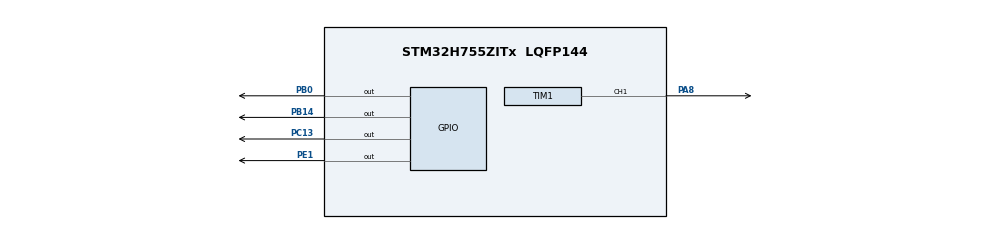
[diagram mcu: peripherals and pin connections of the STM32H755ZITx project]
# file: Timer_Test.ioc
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CortexM4.IPs=FATFS_M4\:I,FREERTOS_M4\:I,IWDG2\:I,RCC,WWDG2\:I,DMA,BDMA,MDMA,NVIC2\:I,USART3,DEBUG,PDM2PCM_M4\:I,PWR,RESMGR_UTILITY,SYS_M4\:I,USB_DEVICE_M4\:I,USB_HOST_M4\:I,CORTEX_M4\:I,GPIO,OPENAMP_M4\:I,VREFBUF,NUCLEO-H755ZI-Q
CortexM4.Pins=PB14
CortexM7.IPs=FATFS_M7\:I,FREERTOS_M7\:I,IWDG1\:I,RCC\:I,WWDG1\:I,DMA\:I,BDMA\:I,MDMA\:I,NVIC1\:I,USART3\:I,SYS\:I,CORTEX_M7\:I,DEBUG\:I,PDM2PCM_M7\:I,PWR\:I,RESMGR_UTILITY\:I,USB_DEVICE_M7\:I,USB_HOST_M7\:I,GPIO\:I,OPENAMP_M7\:I,VREFBUF\:I,NUCLEO-H755ZI-Q\:I,MEMORYMAP\:I,TIM1\:I
CortexM7.Pins=PC13,PB0,PE1
Mcu.Family=STM32H7
Mcu.Name=STM32H755ZITx
Mcu.Package=LQFP144
NUCLEO-H755ZI-Q.BUTTON=0
NUCLEO-H755ZI-Q.LD1=false
NUCLEO-H755ZI-Q.LD2=false
NUCLEO-H755ZI-Q.LD3=false
NUCLEO-H755ZI-Q.VCP=true
NVIC1.PriorityGroup=NVIC_PRIORITYGROUP_4
NVIC2.PriorityGroup=NVIC_PRIORITYGROUP_4
PA13\ (JTMS/SWDIO).Mode=Serial_Wire
PA13\ (JTMS/SWDIO).PinAttribute=CortexM7
PA13\ (JTMS/SWDIO).Signal=DEBUG_JTMS-SWDIO
PA14\ (JTCK/SWCLK).Mode=Serial_Wire
PA14\ (JTCK/SWCLK).PinAttribute=CortexM7
PA14\ (JTCK/SWCLK).Signal=DEBUG_JTCK-SWCLK
PA8.PinAttribute=CortexM7
PA8.Signal=S_TIM1_CH1
PB0.PinAttribute=CortexM7
PB0.Signal=GPIO_Output
PB13.Signal=ETH_TXD1
PB14.PinAttribute=CortexM4
PB14.Signal=GPIO_Output
PC13.PinAttribute=CortexM7
PC13.Signal=GPIO_Output
PC14-OSC32_IN\ (OSC32_IN).PinAttribute=Free
PC14-OSC32_IN\ (OSC32_IN).Signal=RCC_OSC32_IN
PC15-OSC32_OUT\ (OSC32_OUT).PinAttribute=Free
PC15-OSC32_OUT\ (OSC32_OUT).Signal=RCC_OSC32_OUT
PD8.Signal=USART3_TX
PD9.Signal=USART3_RX
PE1.PinAttribute=CortexM7
PE1.Signal=GPIO_Output
PH0-OSC_IN\ (PH0).PinAttribute=Free
PH0-OSC_IN\ (PH0).Signal=RCC_OSC_IN
PH1-OSC_OUT\ (PH1).PinAttribute=Free
PH1-OSC_OUT\ (PH1).Signal=RCC_OSC_OUT
ProjectManager.HeapSize=M4-0x200,M7-0x200
ProjectManager.StackSize=M4-0x400,M7-0x400
ProjectManager.TargetToolchain=STM32CubeIDE
RCC.ADCFreq_Value=129000000
RCC.APB1Freq_Value=100000000
RCC.APB2Freq_Value=100000000
RCC.APB3Freq_Value=100000000
RCC.APB4Freq_Value=100000000
RCC.CortexFreq_Value=400000000
RCC.D1PPRE=RCC_APB3_DIV2
RCC.D2PPRE1=RCC_APB1_DIV2
RCC.D2PPRE2=RCC_APB2_DIV2
RCC.D3PPRE=RCC_APB4_DIV2
RCC.DIVM1=4
RCC.DIVN1=50
RCC.DIVQ1=5
RCC.HCLKFreq_Value=200000000
RCC.HPRE=RCC_HCLK_DIV2
RCC.PLL2FRACN=0
RCC.PLL3FRACN=0
RCC.PLLFRACN=0
RCC.SYSCLKFreq_VALUE=400000000
RCC.SYSCLKSource=RCC_SYSCLKSOURCE_PLLCLK
RCC.SupplySource=PWR_DIRECT_SMPS_SUPPLY
RCC.USBFreq_Value=160000000
SH.S_TIM1_CH1.0=TIM1_CH1,PWM Generation1 CH1
TIM1.Channel-PWM\ Generation1\ CH1=TIM_CHANNEL_1
TIM1.ClockDivision=TIM_CLOCKDIVISION_DIV1
TIM1.Period=19
TIM1.Prescaler=4
TIM1.Pulse-PWM\ Generation1\ CH1=10
VP_MEMORYMAP_VS_MEMORYMAP.Mode=CurAppReg
VP_NUCLEO-H755ZI-Q_VS_BSP_COMMON.Mode=COMMON
VP_SYS_M4_VS_Systick.Mode=SysTick
VP_TIM1_VS_ClockSourceINT.Mode=Internal
board=NUCLEO-H755ZI-Q

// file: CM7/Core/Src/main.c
/* USER CODE BEGIN Header */
/**
  ******************************************************************************
  * @file           : main.c
  * @brief          : Main program body
  ******************************************************************************
  * @attention
  *
  * Copyright (c) 2025 STMicroelectronics.
  * All rights reserved.
  *
  * This software is licensed under terms that can be found in the LICENSE file
  * in the root directory of this software component.
  * If no LICENSE file comes with this software, it is provided AS-IS.
  *
  ******************************************************************************
  */
/* USER CODE END Header */
#include "main.h"

/* USER CODE BEGIN PD */

#ifndef HSEM_ID_0
#define HSEM_ID_0 (0U) /* HW semaphore 0*/
#endif

/* USER CODE END PD */

COM_InitTypeDef BspCOMInit;

TIM_HandleTypeDef htim1;

void SystemClock_Config(void);
static void MX_GPIO_Init(void);
static void MX_TIM1_Init(void);

int main(void)
{

/* USER CODE BEGIN Boot_Mode_Sequence_0 */
  int32_t timeout;
/* USER CODE END Boot_Mode_Sequence_0 */

/* USER CODE BEGIN Boot_Mode_Sequence_1 */
  /* Wait until CPU2 boots and enters in stop mode or timeout*/
  timeout = 0xFFFF;
  while((__HAL_RCC_GET_FLAG(RCC_FLAG_D2CKRDY) != RESET) && (timeout-- > 0));
  if ( timeout < 0 )
  {
  Error_Handler();
  }
/* USER CODE END Boot_Mode_Sequence_1 */
  /* MCU Configuration--------------------------------------------------------*/

  /* Reset of all peripherals, Initializes the Flash interface and the Systick. */
  HAL_Init();

  /* Configure the system clock */
  SystemClock_Config();
/* USER CODE BEGIN Boot_Mode_Sequence_2 */
/* When system initialization is finished, Cortex-M7 will release Cortex-M4 by means of
HSEM notification */
/*HW semaphore Clock enable*/
__HAL_RCC_HSEM_CLK_ENABLE();
/*Take HSEM */
HAL_HSEM_FastTake(HSEM_ID_0);
/*Release HSEM in order to notify the CPU2(CM4)*/
HAL_HSEM_Release(HSEM_ID_0,0);
/* wait until CPU2 wakes up from stop mode */
timeout = 0xFFFF;
while((__HAL_RCC_GET_FLAG(RCC_FLAG_D2CKRDY) == RESET) && (timeout-- > 0));
if ( timeout < 0 )
{
Error_Handler();
}
/* USER CODE END Boot_Mode_Sequence_2 */

  /* Initialize all configured peripherals */
  MX_GPIO_Init();
  MX_TIM1_Init();

  /* Initialize COM1 port (115200, 8 bits (7-bit data + 1 stop bit), no parity */
  BspCOMInit.BaudRate   = 115200;
  BspCOMInit.WordLength = COM_WORDLENGTH_8B;
  BspCOMInit.StopBits   = COM_STOPBITS_1;
  BspCOMInit.Parity     = COM_PARITY_NONE;
  BspCOMInit.HwFlowCtl  = COM_HWCONTROL_NONE;
  if (BSP_COM_Init(COM1, &BspCOMInit) != BSP_ERROR_NONE)
  {
    Error_Handler();
  }

  /* Infinite loop */
  while (1)
  {

    /* USER CODE BEGIN 3 */
	  HAL_GPIO_TogglePin(GPIOB, GPIO_PIN_0);
	  HAL_Delay(1000);
	  printf("Hello_Word");
  }
  /* USER CODE END 3 */
}

void SystemClock_Config(void)
{
  RCC_OscInitTypeDef RCC_OscInitStruct = {0};
  RCC_ClkInitTypeDef RCC_ClkInitStruct = {0};

  /** Supply configuration update enable
  */
  HAL_PWREx_ConfigSupply(PWR_DIRECT_SMPS_SUPPLY);

  /** Configure the main internal regulator output voltage
  */
  __HAL_PWR_VOLTAGESCALING_CONFIG(PWR_REGULATOR_VOLTAGE_SCALE1);

  while(!__HAL_PWR_GET_FLAG(PWR_FLAG_VOSRDY)) {}

  /** Initializes the RCC Oscillators according to the specified parameters
  * in the RCC_OscInitTypeDef structure.
  */
  RCC_OscInitStruct.OscillatorType = RCC_OSCILLATORTYPE_HSI;
  RCC_OscInitStruct.HSIState = RCC_HSI_DIV1;
  RCC_OscInitStruct.HSICalibrationValue = RCC_HSICALIBRATION_DEFAULT;
  RCC_OscInitStruct.PLL.PLLState = RCC_PLL_ON;
  RCC_OscInitStruct.PLL.PLLSource = RCC_PLLSOURCE_HSI;
  RCC_OscInitStruct.PLL.PLLM = 4;
  RCC_OscInitStruct.PLL.PLLN = 50;
  RCC_OscInitStruct.PLL.PLLP = 2;
  RCC_OscInitStruct.PLL.PLLQ = 5;
  RCC_OscInitStruct.PLL.PLLR = 2;
  RCC_OscInitStruct.PLL.PLLRGE = RCC_PLL1VCIRANGE_3;
  RCC_OscInitStruct.PLL.PLLVCOSEL = RCC_PLL1VCOWIDE;
  RCC_OscInitStruct.PLL.PLLFRACN = 0;
  if (HAL_RCC_OscConfig(&RCC_OscInitStruct) != HAL_OK)
  {
    Error_Handler();
  }

  /** Initializes the CPU, AHB and APB buses clocks
  */
  RCC_ClkInitStruct.ClockType = RCC_CLOCKTYPE_HCLK|RCC_CLOCKTYPE_SYSCLK
                              |RCC_CLOCKTYPE_PCLK1|RCC_CLOCKTYPE_PCLK2
                              |RCC_CLOCKTYPE_D3PCLK1|RCC_CLOCKTYPE_D1PCLK1;
  RCC_ClkInitStruct.SYSCLKSource = RCC_SYSCLKSOURCE_PLLCLK;
  RCC_ClkInitStruct.SYSCLKDivider = RCC_SYSCLK_DIV1;
  RCC_ClkInitStruct.AHBCLKDivider = RCC_HCLK_DIV2;
  RCC_ClkInitStruct.APB3CLKDivider = RCC_APB3_DIV2;
  RCC_ClkInitStruct.APB1CLKDivider = RCC_APB1_DIV2;
  RCC_ClkInitStruct.APB2CLKDivider = RCC_APB2_DIV2;
  RCC_ClkInitStruct.APB4CLKDivider = RCC_APB4_DIV2;

  if (HAL_RCC_ClockConfig(&RCC_ClkInitStruct, FLASH_LATENCY_2) != HAL_OK)
  {
    Error_Handler();
  }
}

static void MX_TIM1_Init(void)
{

  TIM_ClockConfigTypeDef sClockSourceConfig = {0};
  TIM_MasterConfigTypeDef sMasterConfig = {0};
  TIM_OC_InitTypeDef sConfigOC = {0};
  TIM_BreakDeadTimeConfigTypeDef sBreakDeadTimeConfig = {0};

  htim1.Instance = TIM1;
  htim1.Init.Prescaler = 4;
  htim1.Init.CounterMode = TIM_COUNTERMODE_UP;
  htim1.Init.Period = 19;
  htim1.Init.ClockDivision = TIM_CLOCKDIVISION_DIV1;
  htim1.Init.RepetitionCounter = 0;
  htim1.Init.AutoReloadPreload = TIM_AUTORELOAD_PRELOAD_DISABLE;
  if (HAL_TIM_Base_Init(&htim1) != HAL_OK)
  {
    Error_Handler();
  }
  sClockSourceConfig.ClockSource = TIM_CLOCKSOURCE_INTERNAL;
  if (HAL_TIM_ConfigClockSource(&htim1, &sClockSourceConfig) != HAL_OK)
  {
    Error_Handler();
  }
  if (HAL_TIM_PWM_Init(&htim1) != HAL_OK)
  {
    Error_Handler();
  }
  sMasterConfig.MasterOutputTrigger = TIM_TRGO_RESET;
  sMasterConfig.MasterOutputTrigger2 = TIM_TRGO2_RESET;
  sMasterConfig.MasterSlaveMode = TIM_MASTERSLAVEMODE_DISABLE;
  if (HAL_TIMEx_MasterConfigSynchronization(&htim1, &sMasterConfig) != HAL_OK)
  {
    Error_Handler();
  }
  sConfigOC.OCMode = TIM_OCMODE_PWM1;
  sConfigOC.Pulse = 10;
  sConfigOC.OCPolarity = TIM_OCPOLARITY_HIGH;
  sConfigOC.OCNPolarity = TIM_OCNPOLARITY_HIGH;
  sConfigOC.OCFastMode = TIM_OCFAST_DISABLE;
  sConfigOC.OCIdleState = TIM_OCIDLESTATE_RESET;
  sConfigOC.OCNIdleState = TIM_OCNIDLESTATE_RESET;
  if (HAL_TIM_PWM_ConfigChannel(&htim1, &sConfigOC, TIM_CHANNEL_1) != HAL_OK)
  {
    Error_Handler();
  }
  sBreakDeadTimeConfig.OffStateRunMode = TIM_OSSR_DISABLE;
  sBreakDeadTimeConfig.OffStateIDLEMode = TIM_OSSI_DISABLE;
  sBreakDeadTimeConfig.LockLevel = TIM_LOCKLEVEL_OFF;
  sBreakDeadTimeConfig.DeadTime = 0;
  sBreakDeadTimeConfig.BreakState = TIM_BREAK_DISABLE;
  sBreakDeadTimeConfig.BreakPolarity = TIM_BREAKPOLARITY_HIGH;
  sBreakDeadTimeConfig.BreakFilter = 0;
  sBreakDeadTimeConfig.Break2State = TIM_BREAK2_DISABLE;
  sBreakDeadTimeConfig.Break2Polarity = TIM_BREAK2POLARITY_HIGH;
  sBreakDeadTimeConfig.Break2Filter = 0;
  sBreakDeadTimeConfig.AutomaticOutput = TIM_AUTOMATICOUTPUT_DISABLE;
  if (HAL_TIMEx_ConfigBreakDeadTime(&htim1, &sBreakDeadTimeConfig) != HAL_OK)
  {
    Error_Handler();
  }
  /* USER CODE BEGIN TIM1_Init 2 */
  HAL_TIM_PWM_Start(&htim1, TIM_CHANNEL_1);
  /* USER CODE END TIM1_Init 2 */
  HAL_TIM_MspPostInit(&htim1);

}

static void MX_GPIO_Init(void)
{
  GPIO_InitTypeDef GPIO_InitStruct = {0};

  /* GPIO Ports Clock Enable */
  __HAL_RCC_GPIOC_CLK_ENABLE();
  __HAL_RCC_GPIOB_CLK_ENABLE();
  __HAL_RCC_GPIOA_CLK_ENABLE();
  __HAL_RCC_GPIOE_CLK_ENABLE();

  /*Configure GPIO pin Output Level */
  HAL_GPIO_WritePin(GPIOC, GPIO_PIN_13, GPIO_PIN_RESET);

  /*Configure GPIO pin Output Level */
  HAL_GPIO_WritePin(GPIOB, GPIO_PIN_0, GPIO_PIN_RESET);

  /*Configure GPIO pin Output Level */
  HAL_GPIO_WritePin(GPIOE, GPIO_PIN_1, GPIO_PIN_RESET);

  /*Configure GPIO pin : PC13 */
  GPIO_InitStruct.Pin = GPIO_PIN_13;
  GPIO_InitStruct.Mode = GPIO_MODE_OUTPUT_PP;
  GPIO_InitStruct.Pull = GPIO_NOPULL;
  GPIO_InitStruct.Speed = GPIO_SPEED_FREQ_LOW;
  HAL_GPIO_Init(GPIOC, &GPIO_InitStruct);

  /*Configure GPIO pin : PB0 */
  GPIO_InitStruct.Pin = GPIO_PIN_0;
  GPIO_InitStruct.Mode = GPIO_MODE_OUTPUT_PP;
  GPIO_InitStruct.Pull = GPIO_NOPULL;
  GPIO_InitStruct.Speed = GPIO_SPEED_FREQ_LOW;
  HAL_GPIO_Init(GPIOB, &GPIO_InitStruct);

  /*Configure GPIO pin : PE1 */
  GPIO_InitStruct.Pin = GPIO_PIN_1;
  GPIO_InitStruct.Mode = GPIO_MODE_OUTPUT_PP;
  GPIO_InitStruct.Pull = GPIO_NOPULL;
  GPIO_InitStruct.Speed = GPIO_SPEED_FREQ_LOW;
  HAL_GPIO_Init(GPIOE, &GPIO_InitStruct);

}

void Error_Handler(void)
{
  __disable_irq();
  while (1)
  {
  }
}
